# HC32M458 register map
File version: 1.0
CPU: CM4 r0p1, little endian, MPU, FPU, 4 interrupt priority bits
Registers are 16-bit, read-write, reset 0x0 unless marked. A register's access mark holds for its fields unless they carry their own. Offsets are from the block's base; [hi:lo] are bit positions; {n}, {i} and the like mark numbered series; 'fields as' and 'values as' point back to an identical list.

## CRC
Base 0x40050400
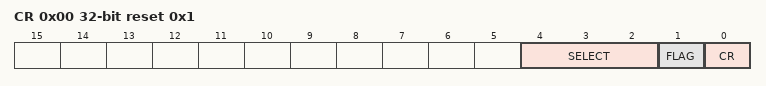
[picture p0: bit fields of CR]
0x00 CR 32-bit reset 0x1
  [4:2] SELECT, [1] FLAG ro, [0] CR
0x04 RESLT1 32-bit
0x08 RESLT2 32-bit
{0x80+4i} DAT{i} 32-bit wo (i=0..31)

## DBGC
Base 0xE0042000
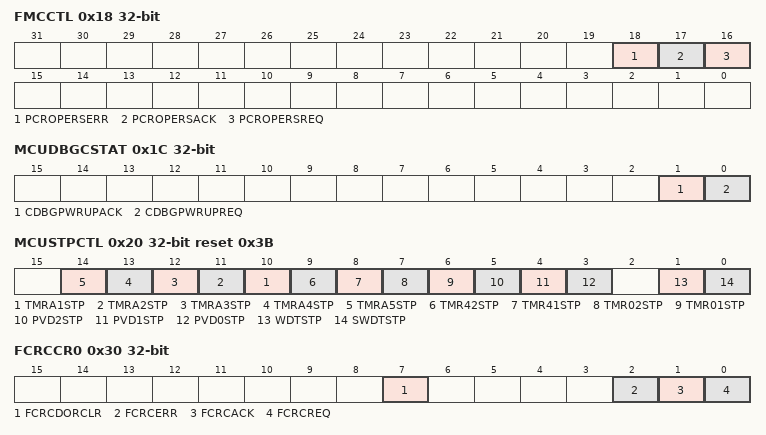
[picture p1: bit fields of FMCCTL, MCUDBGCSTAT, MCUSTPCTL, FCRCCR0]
0x18 FMCCTL 32-bit
  [18] PCROPERSERR, [17] PCROPERSACK, [16] PCROPERSREQ
0x1C MCUDBGCSTAT 32-bit
  [1] CDBGPWRUPACK, [0] CDBGPWRUPREQ
0x20 MCUSTPCTL 32-bit reset 0x3B
  [n+9] TMRA{n}STP (n=1..5), [9] TMR42STP, [8] TMR41STP, [7] TMR02STP, [6] TMR01STP, [5] PVD2STP, [4] PVD1STP, [3] PVD0STP, [1] WDTSTP, [0] SWDTSTP
0x30 FCRCCR0 32-bit
  [7] FCRCDORCLR, [2] FCRCERR, [1] FCRCACK, [0] FCRCREQ
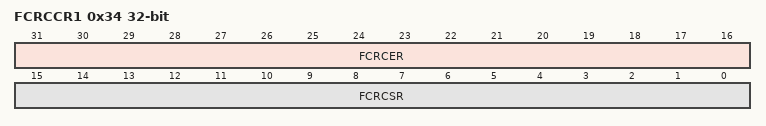
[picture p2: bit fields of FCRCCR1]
0x34 FCRCCR1 32-bit
  [31:16] FCRCER, [15:0] FCRCSR
0x38 FCRCDOR 32-bit ro
0x3C FCRCREF 32-bit ro

## DFM
Base 0x40050000
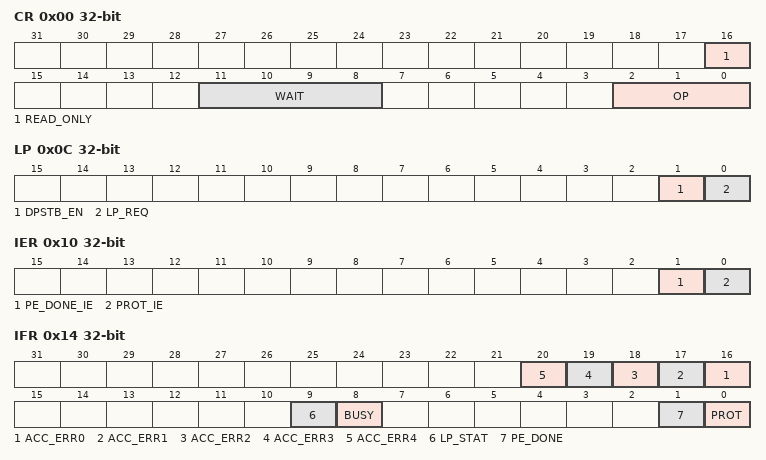
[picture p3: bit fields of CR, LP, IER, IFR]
0x00 CR 32-bit
  [16] READ_ONLY, [11:8] WAIT, [2:0] OP
0x0C LP 32-bit
  [1] DPSTB_EN, [0] LP_REQ wo
0x10 IER 32-bit
  [1] PE_DONE_IE, [0] PROT_IE
0x14 IFR 32-bit ro
  [n+16] ACC_ERR{n} (n=0..4), [9] LP_STAT, [8] BUSY, [1] PE_DONE, [0] PROT
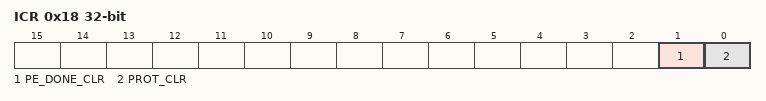
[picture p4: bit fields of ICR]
0x18 ICR 32-bit wo
  [1] PE_DONE_CLR, [0] PROT_CLR
0x2C BYPASS 32-bit wo
  [15:0] BYSEQ
{0x30+4i} SLOCK{i} 32-bit (i=0..3)

## DMA
Base 0x40053000
0x00 EN 32-bit
  [0] EN
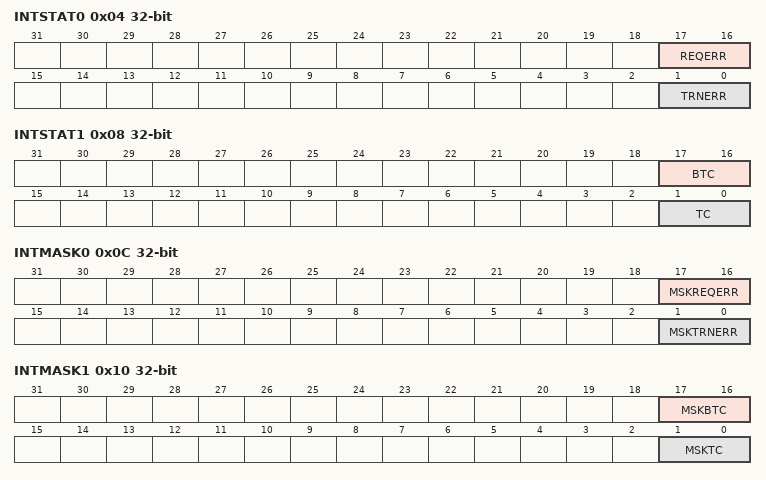
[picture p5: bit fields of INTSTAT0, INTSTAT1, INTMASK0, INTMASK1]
0x04 INTSTAT0 32-bit ro
  [17:16] REQERR, [1:0] TRNERR
0x08 INTSTAT1 32-bit ro
  [17:16] BTC, [1:0] TC
0x0C INTMASK0 32-bit
  [17:16] MSKREQERR, [1:0] MSKTRNERR
0x10 INTMASK1 32-bit
  [17:16] MSKBTC, [1:0] MSKTC
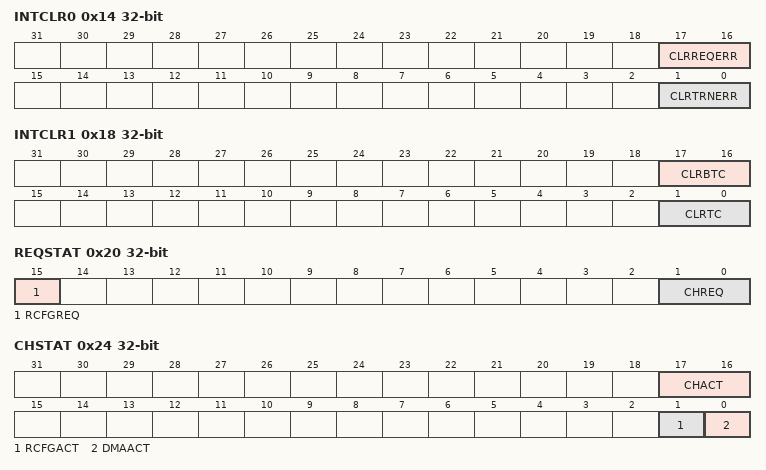
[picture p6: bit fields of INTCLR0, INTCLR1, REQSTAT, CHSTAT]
0x14 INTCLR0 32-bit wo
  [17:16] CLRREQERR, [1:0] CLRTRNERR
0x18 INTCLR1 32-bit wo
  [17:16] CLRBTC, [1:0] CLRTC
0x1C CHEN 32-bit
  [1:0] CHEN
0x20 REQSTAT 32-bit ro
  [15] RCFGREQ, [1:0] CHREQ
0x24 CHSTAT 32-bit ro
  [17:16] CHACT, [1] RCFGACT, [0] DMAACT
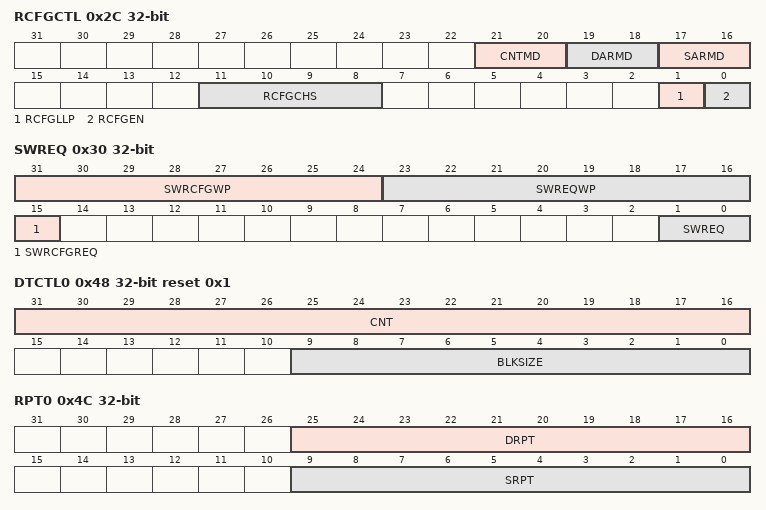
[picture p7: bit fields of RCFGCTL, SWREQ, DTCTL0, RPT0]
0x2C RCFGCTL 32-bit
  [21:20] CNTMD, [19:18] DARMD, [17:16] SARMD, [11:8] RCFGCHS, [1] RCFGLLP, [0] RCFGEN
0x30 SWREQ 32-bit wo
  [31:24] SWRCFGWP, [23:16] SWREQWP, [15] SWRCFGREQ, [1:0] SWREQ
0x34 CHENCLR 32-bit wo
  [1:0] CHENCLR
0x40 SAR0 32-bit
0x44 DAR0 32-bit
0x48 DTCTL0 32-bit reset 0x1
  [31:16] CNT, [9:0] BLKSIZE
0x4C RPT0 32-bit
  [25:16] DRPT, [9:0] SRPT
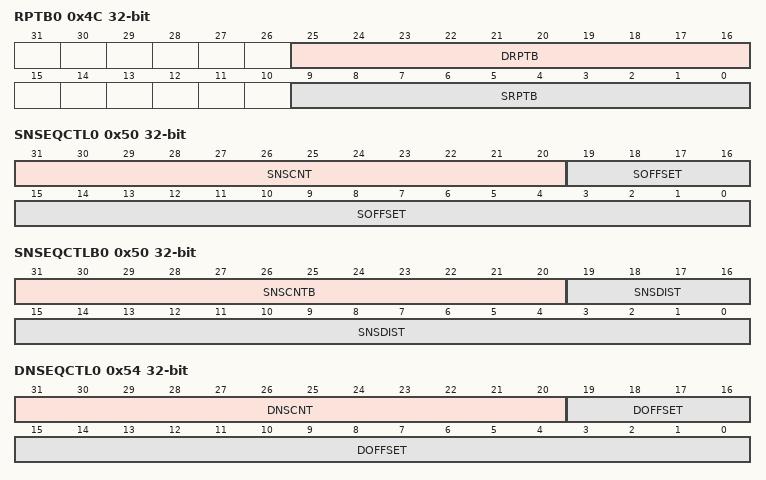
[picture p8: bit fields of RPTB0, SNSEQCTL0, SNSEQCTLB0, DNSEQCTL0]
0x4C RPTB0 32-bit (alternate view of RPT0)
  [25:16] DRPTB, [9:0] SRPTB
0x50 SNSEQCTL0 32-bit
  [31:20] SNSCNT, [19:0] SOFFSET
0x50 SNSEQCTLB0 32-bit (alternate view of SNSEQCTL0)
  [31:20] SNSCNTB, [19:0] SNSDIST
0x54 DNSEQCTL0 32-bit
  [31:20] DNSCNT, [19:0] DOFFSET
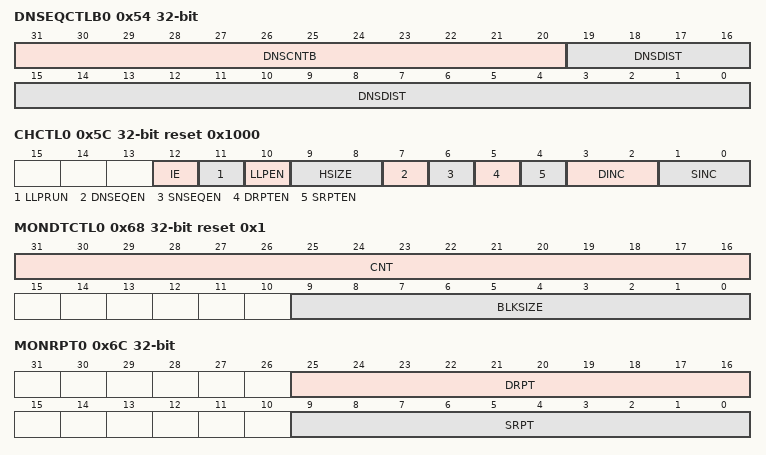
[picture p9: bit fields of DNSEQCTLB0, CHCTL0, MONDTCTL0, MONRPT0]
0x54 DNSEQCTLB0 32-bit (alternate view of DNSEQCTL0)
  [31:20] DNSCNTB, [19:0] DNSDIST
0x58 LLP0 32-bit
  [31:2] LLP
0x5C CHCTL0 32-bit reset 0x1000
  [12] IE, [11] LLPRUN, [10] LLPEN, [9:8] HSIZE, [7] DNSEQEN, [6] SNSEQEN, [5] DRPTEN, [4] SRPTEN, [3:2] DINC, [1:0] SINC
0x60 MONSAR0 32-bit ro
0x64 MONDAR0 32-bit ro
0x68 MONDTCTL0 32-bit ro reset 0x1
  [31:16] CNT, [9:0] BLKSIZE
0x6C MONRPT0 32-bit ro
  [25:16] DRPT, [9:0] SRPT
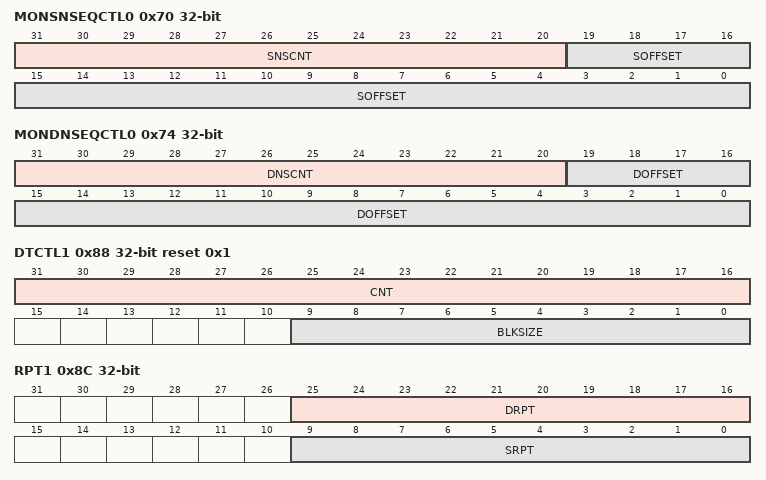
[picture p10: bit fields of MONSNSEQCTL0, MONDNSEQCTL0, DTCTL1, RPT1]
0x70 MONSNSEQCTL0 32-bit ro
  [31:20] SNSCNT, [19:0] SOFFSET
0x74 MONDNSEQCTL0 32-bit ro
  [31:20] DNSCNT, [19:0] DOFFSET
0x80 SAR1 32-bit
0x84 DAR1 32-bit
0x88 DTCTL1 32-bit reset 0x1
  [31:16] CNT, [9:0] BLKSIZE
0x8C RPT1 32-bit
  [25:16] DRPT, [9:0] SRPT
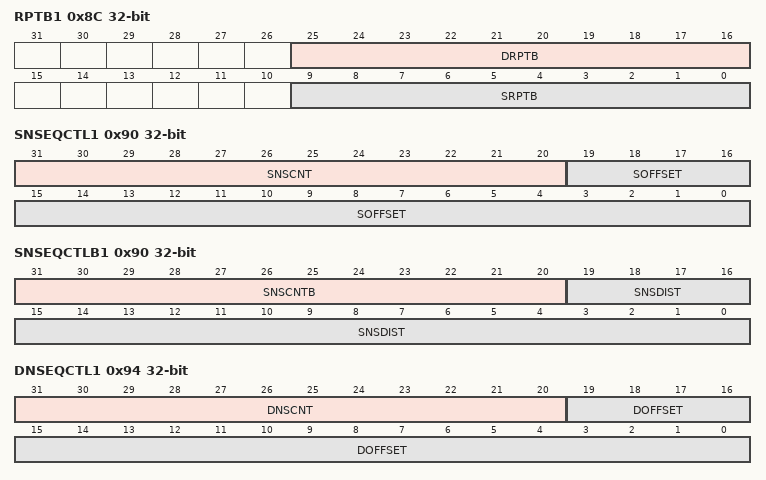
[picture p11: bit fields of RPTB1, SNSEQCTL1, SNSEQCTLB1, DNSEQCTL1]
0x8C RPTB1 32-bit (alternate view of RPT1)
  [25:16] DRPTB, [9:0] SRPTB
0x90 SNSEQCTL1 32-bit
  [31:20] SNSCNT, [19:0] SOFFSET
0x90 SNSEQCTLB1 32-bit (alternate view of SNSEQCTL1)
  [31:20] SNSCNTB, [19:0] SNSDIST
0x94 DNSEQCTL1 32-bit
  [31:20] DNSCNT, [19:0] DOFFSET
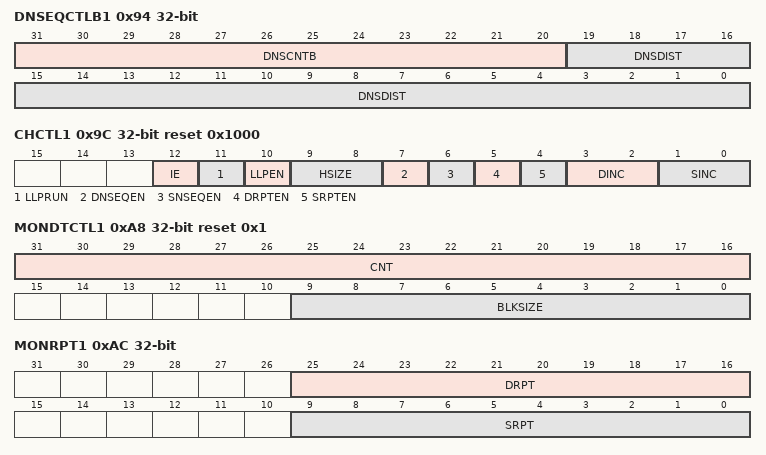
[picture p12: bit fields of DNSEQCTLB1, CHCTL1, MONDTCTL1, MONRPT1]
0x94 DNSEQCTLB1 32-bit (alternate view of DNSEQCTL1)
  [31:20] DNSCNTB, [19:0] DNSDIST
0x98 LLP1 32-bit
  [31:2] LLP
0x9C CHCTL1 32-bit reset 0x1000
  fields as CHCTL0
0xA0 MONSAR1 32-bit ro
0xA4 MONDAR1 32-bit ro
0xA8 MONDTCTL1 32-bit ro reset 0x1
  [31:16] CNT, [9:0] BLKSIZE
0xAC MONRPT1 32-bit ro
  [25:16] DRPT, [9:0] SRPT
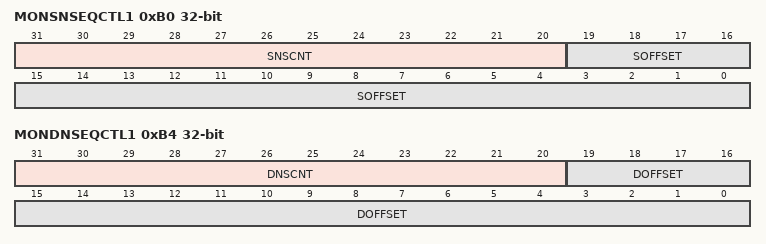
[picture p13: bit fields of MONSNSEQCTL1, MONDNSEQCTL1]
0xB0 MONSNSEQCTL1 32-bit ro
  [31:20] SNSCNT, [19:0] SOFFSET
0xB4 MONDNSEQCTL1 32-bit ro
  [31:20] DNSCNT, [19:0] DOFFSET
